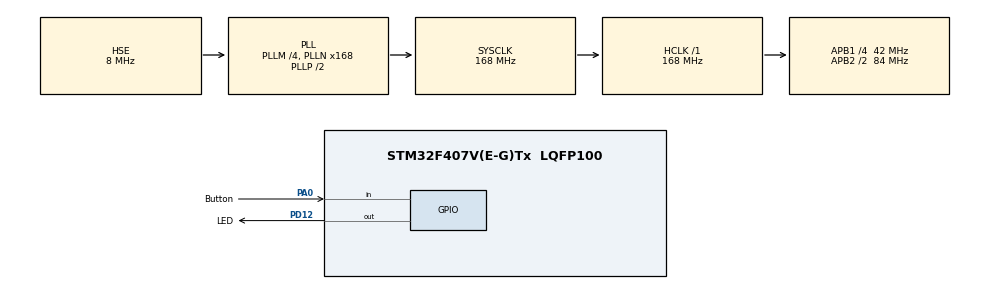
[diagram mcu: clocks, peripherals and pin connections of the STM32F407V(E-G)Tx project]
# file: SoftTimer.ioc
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FREERTOS.Tasks01=defaultTask,0,128,StartDefaultTask,Default
FREERTOS.configTIMER_TASK_PRIORITY=6
FREERTOS.configUSE_TIMERS=1
Mcu.Family=STM32F4
Mcu.Name=STM32F407V(E-G)Tx
Mcu.Package=LQFP100
NVIC.PriorityGroup=NVIC_PRIORITYGROUP_4
NVIC.TIM1_UP_TIM10_IRQn=true\:0\:0\:false\:false\:true
NVIC.TimeBase=TIM1_UP_TIM10_IRQn
NVIC.TimeBaseIP=TIM1
PA0-WKUP.GPIO_Label=Button
PA0-WKUP.Signal=GPIO_Input
PA13.Mode=Serial-Wire
PA13.Signal=SYS_JTMS-SWDIO
PA14.Mode=Serial-Wire
PA14.Signal=SYS_JTCK-SWCLK
PD12.GPIO_Label=LED
PD12.GPIO_Speed=GPIO_SPEED_FREQ_VERY_HIGH
PD12.PinState=GPIO_PIN_SET
PD12.Signal=GPIO_Output
PH0-OSC_IN.Mode=HSE-External-Oscillator
PH0-OSC_IN.Signal=RCC_OSC_IN
PH1-OSC_OUT.Mode=HSE-External-Oscillator
PH1-OSC_OUT.Signal=RCC_OSC_OUT
ProjectManager.HeapSize=0x200
ProjectManager.StackSize=0x400
ProjectManager.TargetToolchain=MDK-ARM V5
RCC.48MHZClocksFreq_Value=84000000
RCC.AHBFreq_Value=168000000
RCC.APB1CLKDivider=RCC_HCLK_DIV4
RCC.APB1Freq_Value=42000000
RCC.APB1TimCLKDivider=1
RCC.APB1TimFreq_Value=42000000
RCC.APB2CLKDivider=RCC_HCLK_DIV2
RCC.APB2Freq_Value=84000000
RCC.APB2TimCLKDivider=1
RCC.APB2TimFreq_Value=84000000
RCC.CortexFreq_Value=168000000
RCC.HCLKFreq_Value=168000000
RCC.HSE_VALUE=8000000
RCC.HSI_VALUE=16000000
RCC.LSE_VALUE=32768
RCC.PLLM=4
RCC.PLLN=168
RCC.PLLSourceVirtual=RCC_PLLSOURCE_HSE
RCC.SYSCLKFreq_VALUE=168000000
RCC.SYSCLKSource=RCC_SYSCLKSOURCE_PLLCLK
RCC.VCOOutputFreq_Value=336000000
VP_FREERTOS_VS_ENABLE.Mode=Enabled
VP_SYS_VS_tim1.Mode=TIM1
board=SoftTimer

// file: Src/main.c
/**
  ******************************************************************************
  * File Name          : main.c
  * Description        : Main program body
  ******************************************************************************
  *
  * COPYRIGHT(c) 2021 STMicroelectronics
  *
  * Redistribution and use in source and binary forms, with or without modification,
  * are permitted provided that the following conditions are met:
  *   1. Redistributions of source code must retain the above copyright notice,
  *      this list of conditions and the following disclaimer.
  *   2. Redistributions in binary form must reproduce the above copyright notice,
  *      this list of conditions and the following disclaimer in the documentation
  *      and/or other materials provided with the distribution.
  *   3. Neither the name of STMicroelectronics nor the names of its contributors
  *      may be used to endorse or promote products derived from this software
  *      without specific prior written permission.
  *
  * THIS SOFTWARE IS PROVIDED BY THE COPYRIGHT HOLDERS AND CONTRIBUTORS "AS IS"
  * AND ANY EXPRESS OR IMPLIED WARRANTIES, INCLUDING, BUT NOT LIMITED TO, THE
  * IMPLIED WARRANTIES OF MERCHANTABILITY AND FITNESS FOR A PARTICULAR PURPOSE ARE
  * DISCLAIMED. IN NO EVENT SHALL THE COPYRIGHT HOLDER OR CONTRIBUTORS BE LIABLE
  * FOR ANY DIRECT, INDIRECT, INCIDENTAL, SPECIAL, EXEMPLARY, OR CONSEQUENTIAL
  * DAMAGES (INCLUDING, BUT NOT LIMITED TO, PROCUREMENT OF SUBSTITUTE GOODS OR
  * SERVICES; LOSS OF USE, DATA, OR PROFITS; OR BUSINESS INTERRUPTION) HOWEVER
  * CAUSED AND ON ANY THEORY OF LIABILITY, WHETHER IN CONTRACT, STRICT LIABILITY,
  * OR TORT (INCLUDING NEGLIGENCE OR OTHERWISE) ARISING IN ANY WAY OUT OF THE USE
  * OF THIS SOFTWARE, EVEN IF ADVISED OF THE POSSIBILITY OF SUCH DAMAGE.
  *
  ******************************************************************************
  */
#include "stm32f4xx_hal.h"
#include "cmsis_os.h"

/* USER CODE BEGIN PV */
/* Private variables ---------------------------------------------------------*/
xTimerHandle PTHandler;	//PeriodicTimer Handler
xTimerHandle OTHandler;	//OnceTimer Handler
xTaskHandle printTaskHandler;	//Print Task Handler
xTaskHandle ledTaskHandler;	//Control led Task handler

/* USER CODE END PV */

void SystemClock_Config(void);
static void MX_GPIO_Init(void);

/* USER CODE BEGIN PFP */
/* Private function prototypes -----------------------------------------------*/
void printTask(void* vParam);
void ledTask(void* vParam);
/* USER CODE END PFP */

/* USER CODE BEGIN 0 */
void TimerCallback(xTimerHandle xTimer)
{
	if(xTimer == PTHandler)	//if callback of Periodic timer
	{
		printf("Send from callback of PT\n\n");
	}
	else if(xTimer == OTHandler)	//if callback of Once timer
	{
		HAL_GPIO_WritePin(LED_GPIO_Port, LED_Pin, GPIO_PIN_RESET);	//turn off led
		printf("Off led by callback of OT\n\n");
	}
}
/* USER CODE END 0 */

int main(void)
{

  /* MCU Configuration----------------------------------------------------------*/

  /* Reset of all peripherals, Initializes the Flash interface and the Systick. */
  HAL_Init();

  /* Configure the system clock */
  SystemClock_Config();

  /* Initialize all configured peripherals */
  MX_GPIO_Init();

  /* USER CODE BEGIN RTOS_TIMERS */
  /* start timers, add new ones, ... */
	/*Periodic timer's period = 1000ms; Once timer's period = 4000ms*/
	PTHandler = xTimerCreate("Periodic Timer", pdMS_TO_TICKS(1000), pdTRUE,(void*) 1, TimerCallback);
	OTHandler = xTimerCreate("Once Timer", pdMS_TO_TICKS(4000), pdFALSE,(void*) 2, TimerCallback);
  /* USER CODE END RTOS_TIMERS */

  /* Create the thread(s) */
  /* definition and creation of defaultTask */

  /* USER CODE BEGIN RTOS_THREADS */
  /* add threads, ... */
	xTaskCreate(printTask, "print task", 128, NULL, 1, &printTaskHandler);
	xTaskCreate(ledTask, "led task", 128, NULL, 1, &ledTaskHandler);

  /* USER CODE END RTOS_THREADS */

  /* Start scheduler */
  osKernelStart();

  /* We should never get here as control is now taken by the scheduler */

  /* Infinite loop */
  while (1)
  {

  }

}

/** System Clock Configuration
*/
void SystemClock_Config(void)
{

  RCC_OscInitTypeDef RCC_OscInitStruct;
  RCC_ClkInitTypeDef RCC_ClkInitStruct;

  __HAL_RCC_PWR_CLK_ENABLE();

  __HAL_PWR_VOLTAGESCALING_CONFIG(PWR_REGULATOR_VOLTAGE_SCALE1);

  RCC_OscInitStruct.OscillatorType = RCC_OSCILLATORTYPE_HSE;
  RCC_OscInitStruct.HSEState = RCC_HSE_ON;
  RCC_OscInitStruct.PLL.PLLState = RCC_PLL_ON;
  RCC_OscInitStruct.PLL.PLLSource = RCC_PLLSOURCE_HSE;
  RCC_OscInitStruct.PLL.PLLM = 4;
  RCC_OscInitStruct.PLL.PLLN = 168;
  RCC_OscInitStruct.PLL.PLLP = RCC_PLLP_DIV2;
  RCC_OscInitStruct.PLL.PLLQ = 4;
  HAL_RCC_OscConfig(&RCC_OscInitStruct);

  RCC_ClkInitStruct.ClockType = RCC_CLOCKTYPE_HCLK|RCC_CLOCKTYPE_SYSCLK
                              |RCC_CLOCKTYPE_PCLK1|RCC_CLOCKTYPE_PCLK2;
  RCC_ClkInitStruct.SYSCLKSource = RCC_SYSCLKSOURCE_PLLCLK;
  RCC_ClkInitStruct.AHBCLKDivider = RCC_SYSCLK_DIV1;
  RCC_ClkInitStruct.APB1CLKDivider = RCC_HCLK_DIV4;
  RCC_ClkInitStruct.APB2CLKDivider = RCC_HCLK_DIV2;
  HAL_RCC_ClockConfig(&RCC_ClkInitStruct, FLASH_LATENCY_5);

  HAL_SYSTICK_Config(HAL_RCC_GetHCLKFreq()/1000);

  HAL_SYSTICK_CLKSourceConfig(SYSTICK_CLKSOURCE_HCLK);

  /* SysTick_IRQn interrupt configuration */
  HAL_NVIC_SetPriority(SysTick_IRQn, 15, 0);
}

/** Configure pins as
        * Analog
        * Input
        * Output
        * EVENT_OUT
        * EXTI
*/
void MX_GPIO_Init(void)
{

  GPIO_InitTypeDef GPIO_InitStruct;

  /* GPIO Ports Clock Enable */
  __HAL_RCC_GPIOH_CLK_ENABLE();
  __HAL_RCC_GPIOA_CLK_ENABLE();
  __HAL_RCC_GPIOD_CLK_ENABLE();

  /*Configure GPIO pin : Button_Pin */
  GPIO_InitStruct.Pin = Button_Pin;
  GPIO_InitStruct.Mode = GPIO_MODE_INPUT;
  GPIO_InitStruct.Pull = GPIO_NOPULL;
  HAL_GPIO_Init(Button_GPIO_Port, &GPIO_InitStruct);

  /*Configure GPIO pin : LED_Pin */
  GPIO_InitStruct.Pin = LED_Pin;
  GPIO_InitStruct.Mode = GPIO_MODE_OUTPUT_PP;
  GPIO_InitStruct.Pull = GPIO_NOPULL;
  GPIO_InitStruct.Speed = GPIO_SPEED_FREQ_VERY_HIGH;
  HAL_GPIO_Init(LED_GPIO_Port, &GPIO_InitStruct);

  /*Configure GPIO pin Output Level */
  HAL_GPIO_WritePin(LED_GPIO_Port, LED_Pin, GPIO_PIN_SET);

}

/* USER CODE BEGIN 4 */
void printTask(void* vParam)
{
	xTimerStart(PTHandler, 0);	//start periodic timer only 1 time
	while(1)
	{
		printf("Enter printTask\n");
		vTaskDelay(pdMS_TO_TICKS(2000));
	}
}
void ledTask(void* vParam)
{
	while(1)
	{
		if( HAL_GPIO_ReadPin(Button_GPIO_Port, Button_Pin) ) //if press button
		{
			HAL_GPIO_WritePin(LED_GPIO_Port, LED_Pin, GPIO_PIN_SET);	//turn on led
			xTimerStart(OTHandler, 0);	//start OnceTimer every press btn
		}
		vTaskDelay(pdMS_TO_TICKS(20));	//this task run every 20ms, maybe not miss any press
	}
}
/* USER CODE END 4 */

/* StartDefaultTask function */
//void StartDefaultTask(void const * argument)
//{

//  /* USER CODE BEGIN 5 */
//  /* Infinite loop */
//  for(;;)
//  {
//    osDelay(1);
//  }
//  /* USER CODE END 5 */
//}

/************************ (C) COPYRIGHT STMicroelectronics *****END OF FILE****/
